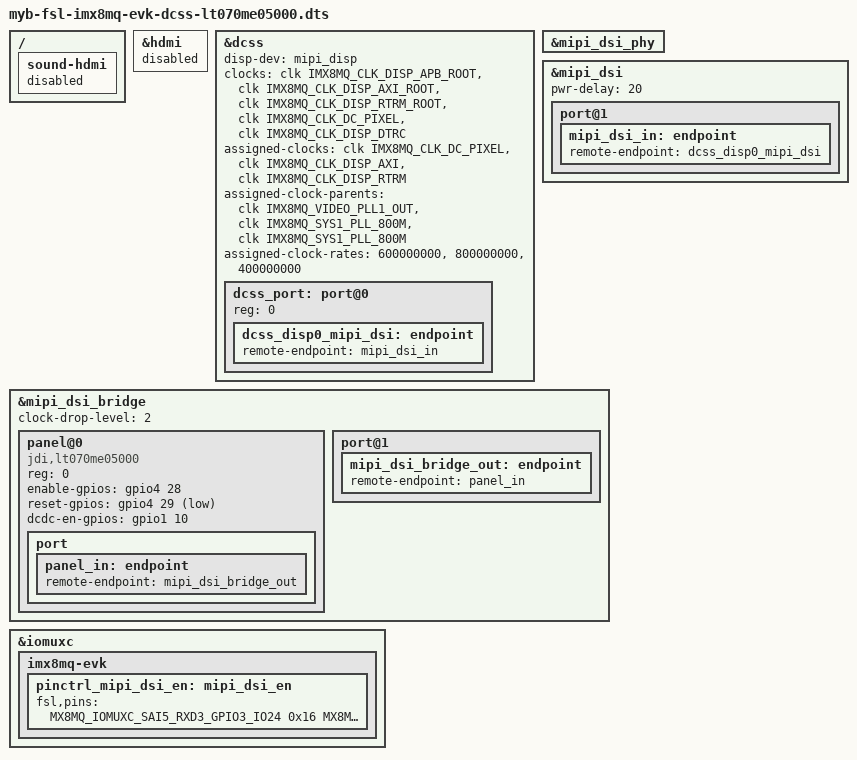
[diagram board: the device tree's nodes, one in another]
/*
 * Copyright 2017 NXP
 *
 * This program is free software; you can redistribute it and/or
 * modify it under the terms of the GNU General Public License
 * as published by the Free Software Foundation; either version 2
 * of the License, or (at your option) any later version.
 *
 * This program is distributed in the hope that it will be useful,
 * but WITHOUT ANY WARRANTY; without even the implied warranty of
 * MERCHANTABILITY or FITNESS FOR A PARTICULAR PURPOSE.  See the
 * GNU General Public License for more details.
 */

#include "myb-fsl-imx8mq-evk.dts"


/ {
	sound-hdmi {
		status = "disabled";
	};

};


/delete-node/ &hdmi_port;

&hdmi {
	status = "disabled";
};

&dcss {
	status = "okay";
	disp-dev = "mipi_disp";

	clocks = <&clk IMX8MQ_CLK_DISP_APB_ROOT>,
		 <&clk IMX8MQ_CLK_DISP_AXI_ROOT>,
		 <&clk IMX8MQ_CLK_DISP_RTRM_ROOT>,
		 <&clk IMX8MQ_CLK_DC_PIXEL>,
		 <&clk IMX8MQ_CLK_DISP_DTRC>;
	clock-names = "apb", "axi", "rtrm", "pix", "dtrc";
	assigned-clocks = <&clk IMX8MQ_CLK_DC_PIXEL>,
			  <&clk IMX8MQ_CLK_DISP_AXI>,
			  <&clk IMX8MQ_CLK_DISP_RTRM>;
	assigned-clock-parents = <&clk IMX8MQ_VIDEO_PLL1_OUT>,
				 <&clk IMX8MQ_SYS1_PLL_800M>,
				 <&clk IMX8MQ_SYS1_PLL_800M>;
	assigned-clock-rates = <600000000>,
			       <800000000>,
			       <400000000>;

	dcss_port: port@0 {
		reg = <0>;

		dcss_disp0_mipi_dsi: endpoint {
			remote-endpoint = <&mipi_dsi_in>;
		};
	};
};

&mipi_dsi_phy {
	status = "okay";
};

&mipi_dsi {
	status = "okay";

	pwr-delay = <20>;
	port@1 {
		mipi_dsi_in: endpoint {
			remote-endpoint = <&dcss_disp0_mipi_dsi>;
		};
	};
};

&mipi_dsi_bridge {
	status = "okay";
	clock-drop-level = <2>;

	panel@0 {
		reg = <0>;
		compatible = "jdi,lt070me05000";
		/*
		vddp-supply = <&pm8921_l17>;
		iovcc-supply = <&pm8921_lvs7>;
		*/
		enable-gpios = <&gpio4 28 GPIO_ACTIVE_HIGH>; 
		reset-gpios = <&gpio4 29 GPIO_ACTIVE_LOW>;
		dcdc-en-gpios = <&gpio1 10 GPIO_ACTIVE_HIGH>;

		port {
			panel_in: endpoint {
				remote-endpoint = <&mipi_dsi_bridge_out>;
			};
		};
	};
	port@1 {
		mipi_dsi_bridge_out: endpoint {
			remote-endpoint = <&panel_in>;
		};
	};
};

&iomuxc {
	imx8mq-evk {
		pinctrl_mipi_dsi_en: mipi_dsi_en {
			fsl,pins = <
				MX8MQ_IOMUXC_SAI5_RXD3_GPIO3_IO24 0x16
				MX8MQ_IOMUXC_SAI3_RXC_GPIO4_IO29	0x16
				
			>;
		};

	};
};





